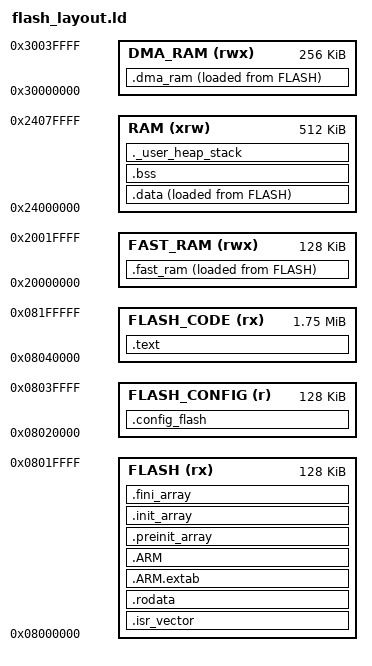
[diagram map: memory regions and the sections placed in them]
/*
*****************************************************************************
**
** Linker script for STM32H743VI Device with
**                2048KByte FLASH, 640KByte RAM
**
*****************************************************************************
*/

/* Entry Point */
ENTRY(Reset_Handler)

/* Highest address of the user mode stack */
_estack = ORIGIN(RAM) + LENGTH(RAM); /* end of "RAM" Ram type memory */

_Min_Heap_Size = 0; /* required amount of heap */
_Min_Stack_Size = 0x400; /* required amount of stack */

/* Memories definition */
MEMORY
{
  FLASH (rx)         : ORIGIN = 0x08000000, LENGTH = 128K
  FLASH_CONFIG (r)   : ORIGIN = 0x08020000, LENGTH = 128K
  FLASH_CODE   (rx)  : ORIGIN = 0x08040000, LENGTH = 1792K
  FAST_RAM (rwx)     : ORIGIN = 0x20000000, LENGTH = 128K
  RAM    (xrw)       : ORIGIN = 0x24000000, LENGTH = 512K
  DMA_RAM (rwx)      : ORIGIN = 0x30000000, LENGTH = 256K
}

/* Sections */
SECTIONS
{
  .config_flash  :
  {
    _config_flash_start = .;
    KEEP(*(.config_flash))
    _config_flash_end = .;
  } >FLASH_CONFIG

  /* The startup code into "FLASH" Rom type memory */
  .isr_vector :
  {
    . = ALIGN(4);
    KEEP(*(.isr_vector)) /* Startup code */
    . = ALIGN(4);
  } >FLASH

  /* The program code and other data into "FLASH_CODE" Rom type memory */
  .text :
  {
    . = ALIGN(4);
    *(.text)           /* .text sections (code) */
    *(.text*)          /* .text* sections (code) */
    *(.glue_7)         /* glue arm to thumb code */
    *(.glue_7t)        /* glue thumb to arm code */
    *(.eh_frame)

    KEEP (*(.init))
    KEEP (*(.fini))

    . = ALIGN(4);
    _etext = .;        /* define a global symbols at end of code */
  } >FLASH_CODE

  /* Constant data into "FLASH" Rom type memory */
  .rodata :
  {
    . = ALIGN(4);
    *(.rodata)         /* .rodata sections (constants, strings, etc.) */
    *(.rodata*)        /* .rodata* sections (constants, strings, etc.) */
    . = ALIGN(4);
  } >FLASH

  .ARM.extab   : {
    . = ALIGN(4);
    *(.ARM.extab* .gnu.linkonce.armextab.*)
    . = ALIGN(4);
  } >FLASH

  .ARM : {
    . = ALIGN(4);
    __exidx_start = .;
    *(.ARM.exidx*)
    __exidx_end = .;
    . = ALIGN(4);
  } >FLASH

  .preinit_array     :
  {
    . = ALIGN(4);
    PROVIDE_HIDDEN (__preinit_array_start = .);
    KEEP (*(.preinit_array*))
    PROVIDE_HIDDEN (__preinit_array_end = .);
    . = ALIGN(4);
  } >FLASH

  .init_array :
  {
    . = ALIGN(4);
    PROVIDE_HIDDEN (__init_array_start = .);
    KEEP (*(SORT(.init_array.*)))
    KEEP (*(.init_array*))
    PROVIDE_HIDDEN (__init_array_end = .);
    . = ALIGN(4);
  } >FLASH

  .fini_array :
  {
    . = ALIGN(4);
    PROVIDE_HIDDEN (__fini_array_start = .);
    KEEP (*(SORT(.fini_array.*)))
    KEEP (*(.fini_array*))
    PROVIDE_HIDDEN (__fini_array_end = .);
    . = ALIGN(4);
  } >FLASH

  /* Used by the startup to initialize data */
  _sidata = LOADADDR(.data);

  /* Initialized data sections into "RAM" Ram type memory */
  .data :
  {
    . = ALIGN(4);
    _sdata = .;        /* create a global symbol at data start */
    *(.data)           /* .data sections */
    *(.data*)          /* .data* sections */
    *(.RamFunc)        /* .RamFunc sections */
    *(.RamFunc*)       /* .RamFunc* sections */

    . = ALIGN(4);
    _edata = .;        /* define a global symbol at data end */

  } >RAM AT> FLASH

  _fast_ram_data = LOADADDR(.fast_ram);
  .fast_ram :
  {
    . = ALIGN(4);
    _fast_ram_start = .;       /* create a global symbol at fast_ram start */
    *(.fast_ram)
    *(.fast_ram*)
    
    . = ALIGN(4);
    _fast_ram_end = .;       /* create a global symbol at fast_ram end */
  } >FAST_RAM AT> FLASH

  _dma_ram_data = LOADADDR(.dma_ram);
  .dma_ram :
  {
    . = ALIGN(4);
    _dma_ram_start = .;       /* create a global symbol at dma_ram start */
    *(.dma_ram)
    *(.dma_ram*)
    
    . = ALIGN(4);
    _dma_ram_end = .;       /* create a global symbol at dma_ram end */
  } >DMA_RAM AT> FLASH

  /* Uninitialized data section into "RAM" Ram type memory */
  . = ALIGN(4);
  .bss :
  {
    /* This is used by the startup in order to initialize the .bss section */
    _sbss = .;         /* define a global symbol at bss start */
    __bss_start__ = _sbss;
    *(.bss)
    *(.bss*)
    *(COMMON)

    . = ALIGN(4);
    _ebss = .;         /* define a global symbol at bss end */
    __bss_end__ = _ebss;
  } >RAM

  /* User_heap_stack section, used to check that there is enough "RAM" Ram  type memory left */
  ._user_heap_stack :
  {
    . = ALIGN(8);
    PROVIDE ( end = . );
    PROVIDE ( _end = . );
    . = . + _Min_Heap_Size;
    . = . + _Min_Stack_Size;
    . = ALIGN(8);
  } >RAM

  /* Remove information from the compiler libraries */
  /DISCARD/ :
  {
    libc.a ( * )
    libm.a ( * )
    libgcc.a ( * )
  }

  .ARM.attributes 0 : { *(.ARM.attributes) }
}
